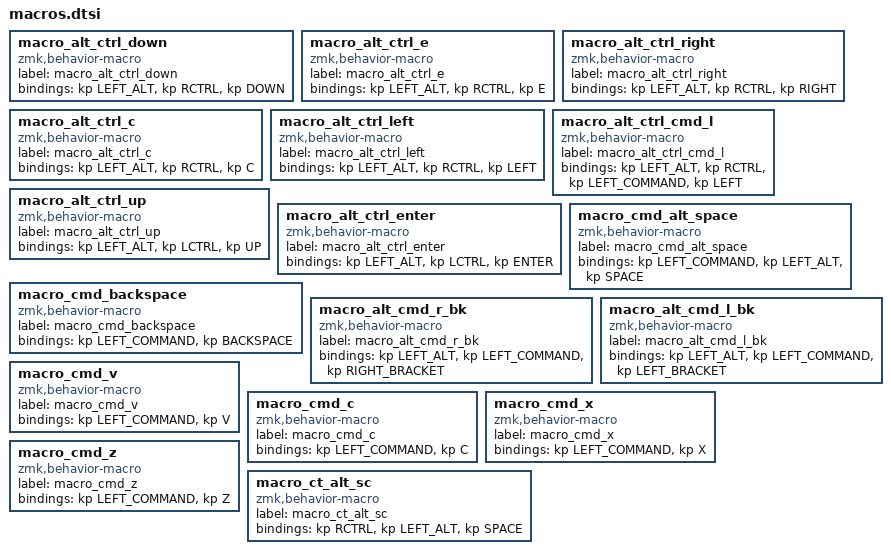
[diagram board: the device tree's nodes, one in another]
macro_alt_ctrl_down: macro_alt_ctrl_down{
compatible = "zmk,behavior-macro";
label = "macro_alt_ctrl_down";
#binding-cells = <0>;
bindings = <&kp LEFT_ALT>, <&kp RCTRL>, <&kp DOWN>;
};
macro_alt_ctrl_e: macro_alt_ctrl_e{
compatible = "zmk,behavior-macro";
label = "macro_alt_ctrl_e";
#binding-cells = <0>;
bindings = <&kp LEFT_ALT>, <&kp RCTRL>, <&kp E>;
};
macro_alt_ctrl_right: macro_alt_ctrl_right{
compatible = "zmk,behavior-macro";
label = "macro_alt_ctrl_right";
#binding-cells = <0>;
bindings = <&kp LEFT_ALT>, <&kp RCTRL>, <&kp RIGHT>;
};
macro_alt_ctrl_c: macro_alt_ctrl_c{
compatible = "zmk,behavior-macro";
label = "macro_alt_ctrl_c";
#binding-cells = <0>;
bindings = <&kp LEFT_ALT>, <&kp RCTRL>, <&kp C>;
};
macro_alt_ctrl_left: macro_alt_ctrl_left{
compatible = "zmk,behavior-macro";
label = "macro_alt_ctrl_left";
#binding-cells = <0>;
bindings = <&kp LEFT_ALT>, <&kp RCTRL>, <&kp LEFT>;
};
macro_alt_ctrl_cmd_l: macro_alt_ctrl_cmd_l{
compatible = "zmk,behavior-macro";
label = "macro_alt_ctrl_cmd_l";
#binding-cells = <0>;
bindings = <&kp LEFT_ALT>, <&kp RCTRL>, <&kp LEFT_COMMAND>, <&kp LEFT>;
};
macro_alt_ctrl_up: macro_alt_ctrl_up{
compatible = "zmk,behavior-macro";
label = "macro_alt_ctrl_up";
#binding-cells = <0>;
bindings = <&kp LEFT_ALT>, <&kp LCTRL>, <&kp UP>;
};
macro_alt_ctrl_enter: macro_alt_ctrl_enter{
compatible = "zmk,behavior-macro";
label = "macro_alt_ctrl_enter";
#binding-cells = <0>;
bindings = <&kp LEFT_ALT>, <&kp LCTRL>, <&kp ENTER>;
};
macro_cmd_alt_space: macro_cmd_alt_space{
compatible = "zmk,behavior-macro";
label = "macro_cmd_alt_space";
#binding-cells = <0>;
bindings = <&kp LEFT_COMMAND>, <&kp LEFT_ALT>, <&kp SPACE>;
};
macro_cmd_backspace: macro_cmd_backspace{
compatible = "zmk,behavior-macro";
label = "macro_cmd_backspace";
#binding-cells = <0>;
bindings = <&kp LEFT_COMMAND>, <&kp BACKSPACE>;
};
macro_alt_cmd_r_bk: macro_alt_cmd_r_bk{
compatible = "zmk,behavior-macro";
label = "macro_alt_cmd_r_bk";
#binding-cells = <0>;
bindings = <&kp LEFT_ALT>, <&kp LEFT_COMMAND>, <&kp RIGHT_BRACKET>;
};
macro_alt_cmd_l_bk: macro_alt_cmd_l_bk{
compatible = "zmk,behavior-macro";
label = "macro_alt_cmd_l_bk";
#binding-cells = <0>;
bindings = <&kp LEFT_ALT>, <&kp LEFT_COMMAND>, <&kp LEFT_BRACKET>;
};
macro_cmd_v: macro_cmd_v{
compatible = "zmk,behavior-macro";
label = "macro_cmd_v";
#binding-cells = <0>;
bindings = <&kp LEFT_COMMAND>, <&kp V>;
};
macro_cmd_c: macro_cmd_c{
compatible = "zmk,behavior-macro";
label = "macro_cmd_c";
#binding-cells = <0>;
bindings = <&kp LEFT_COMMAND>, <&kp C>;
};
macro_cmd_x: macro_cmd_x{
compatible = "zmk,behavior-macro";
label = "macro_cmd_x";
#binding-cells = <0>;
bindings = <&kp LEFT_COMMAND>, <&kp X>;
};
macro_cmd_z: macro_cmd_z{
compatible = "zmk,behavior-macro";
label = "macro_cmd_z";
#binding-cells = <0>;
bindings = <&kp LEFT_COMMAND>, <&kp Z>;
};
macro_ct_alt_sc: macro_ct_alt_sc{
compatible = "zmk,behavior-macro";
label = "macro_ct_alt_sc";
#binding-cells = <0>;
bindings = <&kp RCTRL>, <&kp LEFT_ALT>, <&kp SPACE>;
};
